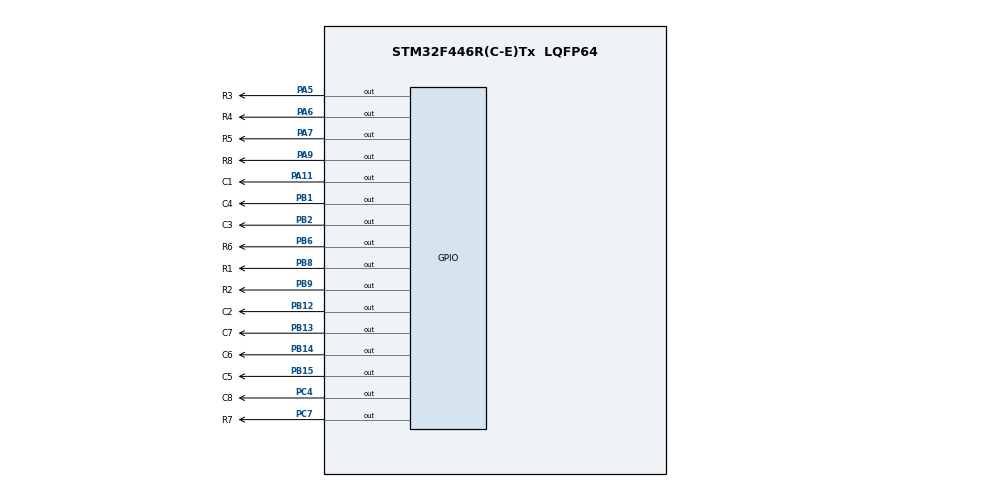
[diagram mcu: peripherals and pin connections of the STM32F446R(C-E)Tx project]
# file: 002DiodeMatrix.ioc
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Mcu.Family=STM32F4
Mcu.Name=STM32F446R(C-E)Tx
Mcu.Package=LQFP64
NVIC.PriorityGroup=NVIC_PRIORITYGROUP_4
PA11.GPIO_Label=C1
PA11.PinState=GPIO_PIN_SET
PA11.Signal=GPIO_Output
PA5.GPIO_Label=R3
PA5.Signal=GPIO_Output
PA6.GPIO_Label=R4
PA6.Signal=GPIO_Output
PA7.GPIO_Label=R5
PA7.Signal=GPIO_Output
PA9.GPIO_Label=R8
PA9.Signal=GPIO_Output
PB1.GPIO_Label=C4
PB1.PinState=GPIO_PIN_SET
PB1.Signal=GPIO_Output
PB12.GPIO_Label=C2
PB12.PinState=GPIO_PIN_SET
PB12.Signal=GPIO_Output
PB13.GPIO_Label=C7
PB13.PinState=GPIO_PIN_SET
PB13.Signal=GPIO_Output
PB14.GPIO_Label=C6
PB14.PinState=GPIO_PIN_SET
PB14.Signal=GPIO_Output
PB15.GPIO_Label=C5
PB15.PinState=GPIO_PIN_SET
PB15.Signal=GPIO_Output
PB2.GPIO_Label=C3
PB2.PinState=GPIO_PIN_SET
PB2.Signal=GPIO_Output
PB6.GPIO_Label=R6
PB6.Signal=GPIO_Output
PB8.GPIO_Label=R1
PB8.Signal=GPIO_Output
PB9.GPIO_Label=R2
PB9.Signal=GPIO_Output
PC4.GPIO_Label=C8
PC4.PinState=GPIO_PIN_SET
PC4.Signal=GPIO_Output
PC7.GPIO_Label=R7
PC7.Signal=GPIO_Output
ProjectManager.HeapSize=0x200
ProjectManager.StackSize=0x400
ProjectManager.TargetToolchain=STM32CubeIDE
RCC.CortexFreq_Value=16000000
RCC.USBFreq_Value=96000000
RCC.VCOOutputFreq_Value=192000000
board=custom

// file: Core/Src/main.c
/* USER CODE BEGIN Header */
/**
  ******************************************************************************
  * @file           : main.c
  * @brief          : Main program body
  ******************************************************************************
  * @attention
  *
  * Copyright (c) 2025 STMicroelectronics.
  * All rights reserved.
  *
  * This software is licensed under terms that can be found in the LICENSE file
  * in the root directory of this software component.
  * If no LICENSE file comes with this software, it is provided AS-IS.
  *
  ******************************************************************************
  */
/* USER CODE END Header */
#include "main.h"

/* USER CODE BEGIN Includes */
#include "render.h"
/* USER CODE END Includes */

void SystemClock_Config(void);
static void MX_GPIO_Init(void);

int main(void)
{

  /* MCU Configuration--------------------------------------------------------*/

  /* Reset of all peripherals, Initializes the Flash interface and the Systick. */
  HAL_Init();

  /* Configure the system clock */
  SystemClock_Config();

  /* Initialize all configured peripherals */
  MX_GPIO_Init();

  /* Infinite loop */
  while (1)
  {
	  //draw_matrix(music);
	  draw_columns(tea);
  }
}

void SystemClock_Config(void)
{
  RCC_OscInitTypeDef RCC_OscInitStruct = {0};
  RCC_ClkInitTypeDef RCC_ClkInitStruct = {0};

  /** Configure the main internal regulator output voltage
  */
  __HAL_RCC_PWR_CLK_ENABLE();
  __HAL_PWR_VOLTAGESCALING_CONFIG(PWR_REGULATOR_VOLTAGE_SCALE3);

  /** Initializes the RCC Oscillators according to the specified parameters
  * in the RCC_OscInitTypeDef structure.
  */
  RCC_OscInitStruct.OscillatorType = RCC_OSCILLATORTYPE_HSI;
  RCC_OscInitStruct.HSIState = RCC_HSI_ON;
  RCC_OscInitStruct.HSICalibrationValue = RCC_HSICALIBRATION_DEFAULT;
  RCC_OscInitStruct.PLL.PLLState = RCC_PLL_NONE;
  if (HAL_RCC_OscConfig(&RCC_OscInitStruct) != HAL_OK)
  {
    Error_Handler();
  }

  /** Initializes the CPU, AHB and APB buses clocks
  */
  RCC_ClkInitStruct.ClockType = RCC_CLOCKTYPE_HCLK|RCC_CLOCKTYPE_SYSCLK
                              |RCC_CLOCKTYPE_PCLK1|RCC_CLOCKTYPE_PCLK2;
  RCC_ClkInitStruct.SYSCLKSource = RCC_SYSCLKSOURCE_HSI;
  RCC_ClkInitStruct.AHBCLKDivider = RCC_SYSCLK_DIV1;
  RCC_ClkInitStruct.APB1CLKDivider = RCC_HCLK_DIV1;
  RCC_ClkInitStruct.APB2CLKDivider = RCC_HCLK_DIV1;

  if (HAL_RCC_ClockConfig(&RCC_ClkInitStruct, FLASH_LATENCY_0) != HAL_OK)
  {
    Error_Handler();
  }
}

static void MX_GPIO_Init(void)
{
  GPIO_InitTypeDef GPIO_InitStruct = {0};

  /* GPIO Ports Clock Enable */
  __HAL_RCC_GPIOA_CLK_ENABLE();
  __HAL_RCC_GPIOC_CLK_ENABLE();
  __HAL_RCC_GPIOB_CLK_ENABLE();

  /*Configure GPIO pin Output Level */
  HAL_GPIO_WritePin(GPIOA, R3_Pin|R4_Pin|R5_Pin|R8_Pin, GPIO_PIN_RESET);

  /*Configure GPIO pin Output Level */
  HAL_GPIO_WritePin(C8_GPIO_Port, C8_Pin, GPIO_PIN_SET);

  /*Configure GPIO pin Output Level */
  HAL_GPIO_WritePin(GPIOB, C4_Pin|C3_Pin|C2_Pin|C7_Pin
                          |C6_Pin|C5_Pin, GPIO_PIN_SET);

  /*Configure GPIO pin Output Level */
  HAL_GPIO_WritePin(R7_GPIO_Port, R7_Pin, GPIO_PIN_RESET);

  /*Configure GPIO pin Output Level */
  HAL_GPIO_WritePin(C1_GPIO_Port, C1_Pin, GPIO_PIN_SET);

  /*Configure GPIO pin Output Level */
  HAL_GPIO_WritePin(GPIOB, R6_Pin|R1_Pin|R2_Pin, GPIO_PIN_RESET);

  /*Configure GPIO pins : R3_Pin R4_Pin R5_Pin R8_Pin
                           C1_Pin */
  GPIO_InitStruct.Pin = R3_Pin|R4_Pin|R5_Pin|R8_Pin
                          |C1_Pin;
  GPIO_InitStruct.Mode = GPIO_MODE_OUTPUT_PP;
  GPIO_InitStruct.Pull = GPIO_NOPULL;
  GPIO_InitStruct.Speed = GPIO_SPEED_FREQ_LOW;
  HAL_GPIO_Init(GPIOA, &GPIO_InitStruct);

  /*Configure GPIO pins : C8_Pin R7_Pin */
  GPIO_InitStruct.Pin = C8_Pin|R7_Pin;
  GPIO_InitStruct.Mode = GPIO_MODE_OUTPUT_PP;
  GPIO_InitStruct.Pull = GPIO_NOPULL;
  GPIO_InitStruct.Speed = GPIO_SPEED_FREQ_LOW;
  HAL_GPIO_Init(GPIOC, &GPIO_InitStruct);

  /*Configure GPIO pins : C4_Pin C3_Pin C2_Pin C7_Pin
                           C6_Pin C5_Pin R6_Pin R1_Pin
                           R2_Pin */
  GPIO_InitStruct.Pin = C4_Pin|C3_Pin|C2_Pin|C7_Pin
                          |C6_Pin|C5_Pin|R6_Pin|R1_Pin
                          |R2_Pin;
  GPIO_InitStruct.Mode = GPIO_MODE_OUTPUT_PP;
  GPIO_InitStruct.Pull = GPIO_NOPULL;
  GPIO_InitStruct.Speed = GPIO_SPEED_FREQ_LOW;
  HAL_GPIO_Init(GPIOB, &GPIO_InitStruct);

}

void Error_Handler(void)
{
  __disable_irq();
  while (1)
  {
  }
}
